# STM32F301 register map
File version: 1.9
CPU: CM4 r1p0, little endian, MPU, FPU, 4 interrupt priority bits
Registers are 32-bit, read-write, reset 0x0 unless marked. A register's access mark holds for its fields unless they carry their own. Offsets are from the block's base; [hi:lo] are bit positions; {n}, {i} and the like mark numbered series; 'fields as' and 'values as' point back to an identical list.

## SYSCFG — System configuration controller
Base 0x40010000
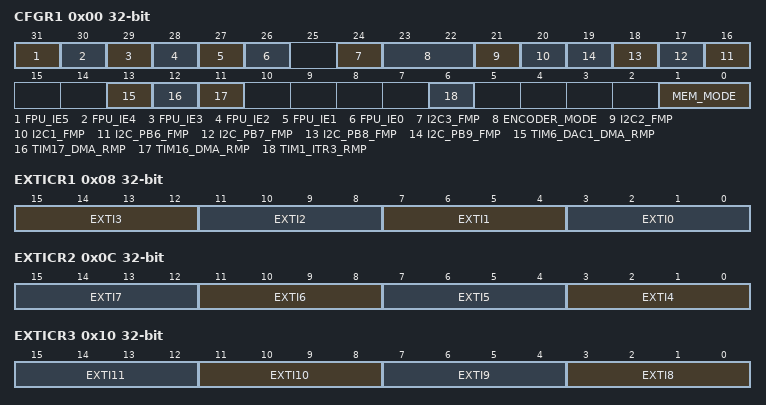
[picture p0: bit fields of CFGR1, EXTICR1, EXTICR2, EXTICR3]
0x00 CFGR1 — configuration register 1
  [31] FPU_IE5 — Inexact interrupt enable
    0=Disabled (Inexact interrupt disable); 1=Enabled (Inexact interrupt enable)
  [30] FPU_IE4 — Input denormal interrupt enable
    0=Disabled (Input denormal interrupt disable); 1=Enabled (Input denormal interrupt enable)
  [29] FPU_IE3 — Overflow interrupt enable
    0=Disabled (Overflow interrupt disable); 1=Enabled (Overflow interrupt enable)
  [28] FPU_IE2 — Underflow interrupt enable
    0=Disabled (Underflow interrupt disable); 1=Enabled (Underflow interrupt enable)
  [27] FPU_IE1 — Devide-by-zero interrupt enable
    0=Disabled (Devide-by-zero interrupt disable); 1=Enabled (Devide-by-zero interrupt enable)
  [26] FPU_IE0 — Invalid operation interrupt enable
    0=Disabled (Invalid operation interrupt disable); 1=Enabled (Invalid operation interrupt enable)
  [24] I2C3_FMP — I2C3 Fast Mode Plus
    0=Standard (FM+ mode is controlled by I2C_Pxx_FMP bits only); 1=FMP (FM+ mode is enabled on all I2C3 pins selected through selection trhough IOPORT control registers AF selection bits)
  [23:22] ENCODER_MODE
    0=NoRedirection; 1=MapTim2Tim15 (TIM2 IC1 and TIM2 IC2 are connected to TIM15 IC1 and TIM15 IC2 respectively)
  [21] I2C2_FMP — I2C2 Fast Mode Plus
    0=Standard (FM+ mode is controlled by I2C_Pxx_FMP bits only); 1=FMP (FM+ mode is enabled on all I2C2 pins selected through selection through IOPORT control registers AF selection bits)
  [20] I2C1_FMP — I2C1 Fast Mode Plus
    0=Standard (FM+ mode is controlled by I2C_Pxx_FMP bits only); 1=FMP (FM+ mode is enabled on all I2C1 pins selected through selection through IOPORT control registers AF selection bits)
  [n+10] I2C_PB{n}_FMP (n=6..9) — Fast Mode Plus (FM+) driving capability activation bits.
    0=Standard (PB{n} pin operate in standard mode); 1=FMP (I2C FM+ mode enabled on PB{n} and the Speed control is bypassed)
  [13] TIM6_DAC1_DMA_RMP — TIM6 and DAC1 DMA request remapping bit
    0=NotRemapped (TIM6_UP and DAC_CH1 DMA requests mapped on DMA2 channel 3); 1=Remapped (TIM6_UP and DAC_CH1 DMA requests mapped on DMA1 channel 3)
  [12] TIM17_DMA_RMP — TIM17 DMA request remapping bit
    0=NotRemapped (TIM17_CH1 and TIM17_UP DMA requests mapped on DMA channel 1); 1=Remapped (TIM17_CH1 and TIM17_UP DMA requests mapped on DMA channel 2)
  [11] TIM16_DMA_RMP — TIM16 DMA request remapping bit
    0=NotRemapped (TIM16_CH1 and TIM16_UP DMA requests mapped on DMA channel 3); 1=Remapped (TIM16_CH1 and TIM16_UP DMA requests mapped on DMA channel 4)
  [6] TIM1_ITR3_RMP — Timer 1 ITR3 selection
    0=NotRemapped; 1=Remapped (TIM1_ITR3 = TIM17_OC)
  [1:0] MEM_MODE — Memory mapping selection bits
    0=Main Flash memory mapped at 0x0000_0000; 1=System Flash memory mapped at 0x0000_0000; 2=MainFlash2 (Main Flash memory mapped at 0x0000_0000); 3=SRAM (Embedded SRAM mapped at 0x0000_0000)
0x08 EXTICR1 — external interrupt configuration register 1
  [15:12] EXTI3 — EXTI 3 configuration bits
    0=PA (Select PAx as the source input for the EXTIx external interrupt); 1=PB (Select PBx as the source input for the EXTIx external interrupt); 2=PC (Select PCx as the source input for the EXTIx external interrupt)
  [11:8] EXTI2 — EXTI 2 configuration bits
    0=PA (Select PAx as the source input for the EXTIx external interrupt); 1=PB (Select PBx as the source input for the EXTIx external interrupt); 2=PC (Select PCx as the source input for the EXTIx external interrupt); 5=PF (Select PFx as the source input for the EXTIX external interrupt)
  [7:4] EXTI1 — EXTI 1 configuration bits
    values as EXTI2
  [3:0] EXTI0 — EXTI 0 configuration bits
    values as EXTI2
0x0C EXTICR2 — external interrupt configuration register 2
  [all] fields
    values as EXTICR1.EXTI3
  [4n-13:4n-16] EXTI{n} (n=4..7) — EXTI {n} configuration bits
0x10 EXTICR3 — external interrupt configuration register 3
  [all] fields
    values as EXTICR1.EXTI3
  [4n-29:4n-32] EXTI{n} (n=8..11) — EXTI {n} configuration bits
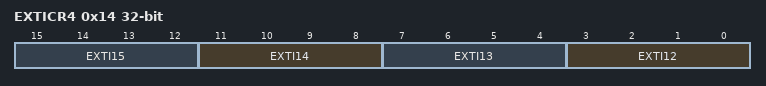
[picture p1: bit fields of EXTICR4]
0x14 EXTICR4 — external interrupt configuration register 4
  [all] fields
    values as EXTICR1.EXTI3
  [4n-45:4n-48] EXTI{n} (n=12..15) — EXTI {n} configuration bits
0x18 CFGR2 — configuration register 2
  [2] PVD_LOCK — PVD lock enable bit
    0=Disconnected (PVD interrupt disconnected from TIM15/16/17 Break input); 1=Connected (PVD interrupt connected to TIM15/16/17 Break input)
